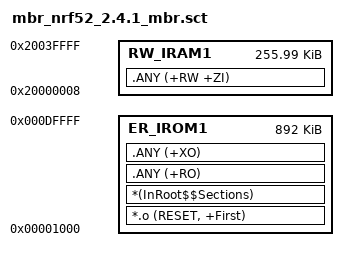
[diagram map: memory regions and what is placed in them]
; *************************************************************
; *** Scatter-Loading Description File generated by uVision ***
; *************************************************************

LR_IROM1 0x00001000 0x000DF000  {    ; load region size_region
  ER_IROM1 0x00001000 0x000DF000  {  ; load address = execution address
   *.o (RESET, +First)
   *(InRoot$$Sections)
   .ANY (+RO)
   .ANY (+XO)
  }
  RW_IRAM1 0x20000008 0x0003FFF8  {  ; RW data
   .ANY (+RW +ZI)
  }
}

